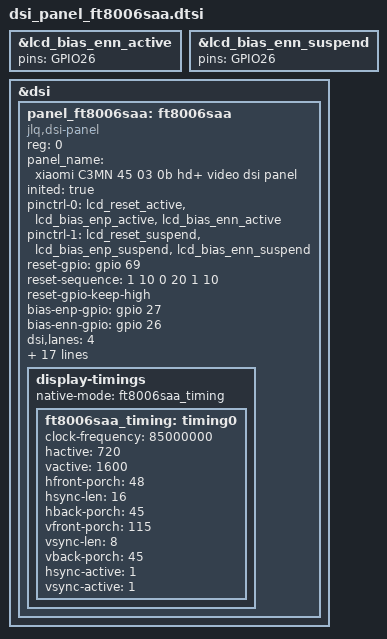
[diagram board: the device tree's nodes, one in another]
&lcd_bias_enn_active {
	pins = "GPIO26";
};

&lcd_bias_enn_suspend {
	pins = "GPIO26";
};

&dsi {
	panel_ft8006saa: ft8006saa {
		compatible = "jlq,dsi-panel";
		reg = <0>;
		panel_name = "xiaomi C3MN 45 03 0b hd+ video dsi panel";
		status = "okay";
		inited = "true";

		pinctrl-names = "panel_active", "panel_suspend";
		pinctrl-0 = <&lcd_reset_active
			&lcd_bias_enp_active
			&lcd_bias_enn_active>;
		pinctrl-1 = <&lcd_reset_suspend
			&lcd_bias_enp_suspend
			&lcd_bias_enn_suspend>;

		reset-gpio = <&gpio 69 0>;
		reset-sequence = <1 10 0 20 1 10>;
		reset-gpio-keep-high;
		bias-enp-gpio = <&gpio 27 0>;
		bias-enn-gpio = <&gpio 26 0>;

		dsi,lanes = <4>;
		dsi,channel = <0>;
		dsi,flags = <0x24400803>;
		dsi,format = <0>;

		init-delay-ms = <35>;
		prepare-delay-ms = <0>;
		enable-delay-ms = <2>;
		unprepare-delay-ms = <0>;
		disable-delay-ms = <2>;
		reset-delay-ms = <10>;
		width-mm = <68>;
		height-mm = <151>;
		backlight-type = <1>;
		ic-vendor = <2>;

		panel-exit-sequence = [
			05 05 01 28
			05 78 01 10
			29 00 02 17 5a
			29 40 02 18 5a
		];

		panel-init-sequence = [
			29 00 02 51 80
			29 00 02 53 2c
			29 00 02 55 00
			29 0a 02 ba 03
			05 64 01 11
			05 0a 01 29
		];

		display-timings {
			native-mode = <&ft8006saa_timing>;
			ft8006saa_timing: timing0 {
				clock-frequency = <85000000>;
				hactive = <720>;
				vactive = <1600>;
				hfront-porch = <48>;
				hsync-len = <16>;
				hback-porch = <45>;
				vfront-porch = <115>;
				vsync-len = <8>;
				vback-porch = <45>;
				hsync-active = <1>;
				vsync-active = <1>;
			};
		};
	};
};
